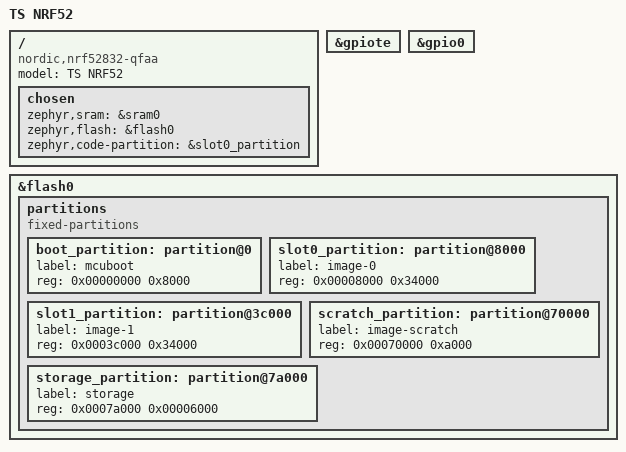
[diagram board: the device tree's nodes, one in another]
/*
 * Copyright (c) 2019 Henrik Brix Andersen <henrik@brixandersen.dk>
 *
 * SPDX-License-Identifier: Apache-2.0
 */

/dts-v1/;
#include <nordic/nrf52832_qfaa.dtsi>

/ {
	model = "TS NRF52";
	compatible = "nordic,nrf52832-qfaa", "nordic,nrf52832";

	chosen {
		zephyr,sram = &sram0;
		zephyr,flash = &flash0;
		zephyr,code-partition = &slot0_partition;
	};
};

&gpiote {
	status = "okay";
};

&gpio0 {
	status = "okay";
};

&flash0 {
	/*
	 * For more information, see:
	 * http://docs.zephyrproject.org/latest/guides/dts/index.html#flash-partitions
	 */
	partitions {
		compatible = "fixed-partitions";
		#address-cells = <1>;
		#size-cells = <1>;

		boot_partition: partition@0 {
			label = "mcuboot";
			reg = <0x00000000 0x8000>;
		};
		slot0_partition: partition@8000 {
			label = "image-0";
			reg = <0x00008000 0x34000>;
		};
		slot1_partition: partition@3c000 {
			label = "image-1";
			reg = <0x0003c000 0x34000>;
		};
		scratch_partition: partition@70000 {
			label = "image-scratch";
			reg = <0x00070000 0xa000>;
		};

		/*
		 * The flash starting at 0x0007a000 and ending at
		 * 0x0007ffff (sectors 122-127) is reserved for use
		 * by the application. If enabled, partition for FCB/NFFS
		 * will be created in this area.
		 */
		storage_partition: partition@7a000 {
			label = "storage";
			reg = <0x0007a000 0x00006000>;
		};
	};
};
